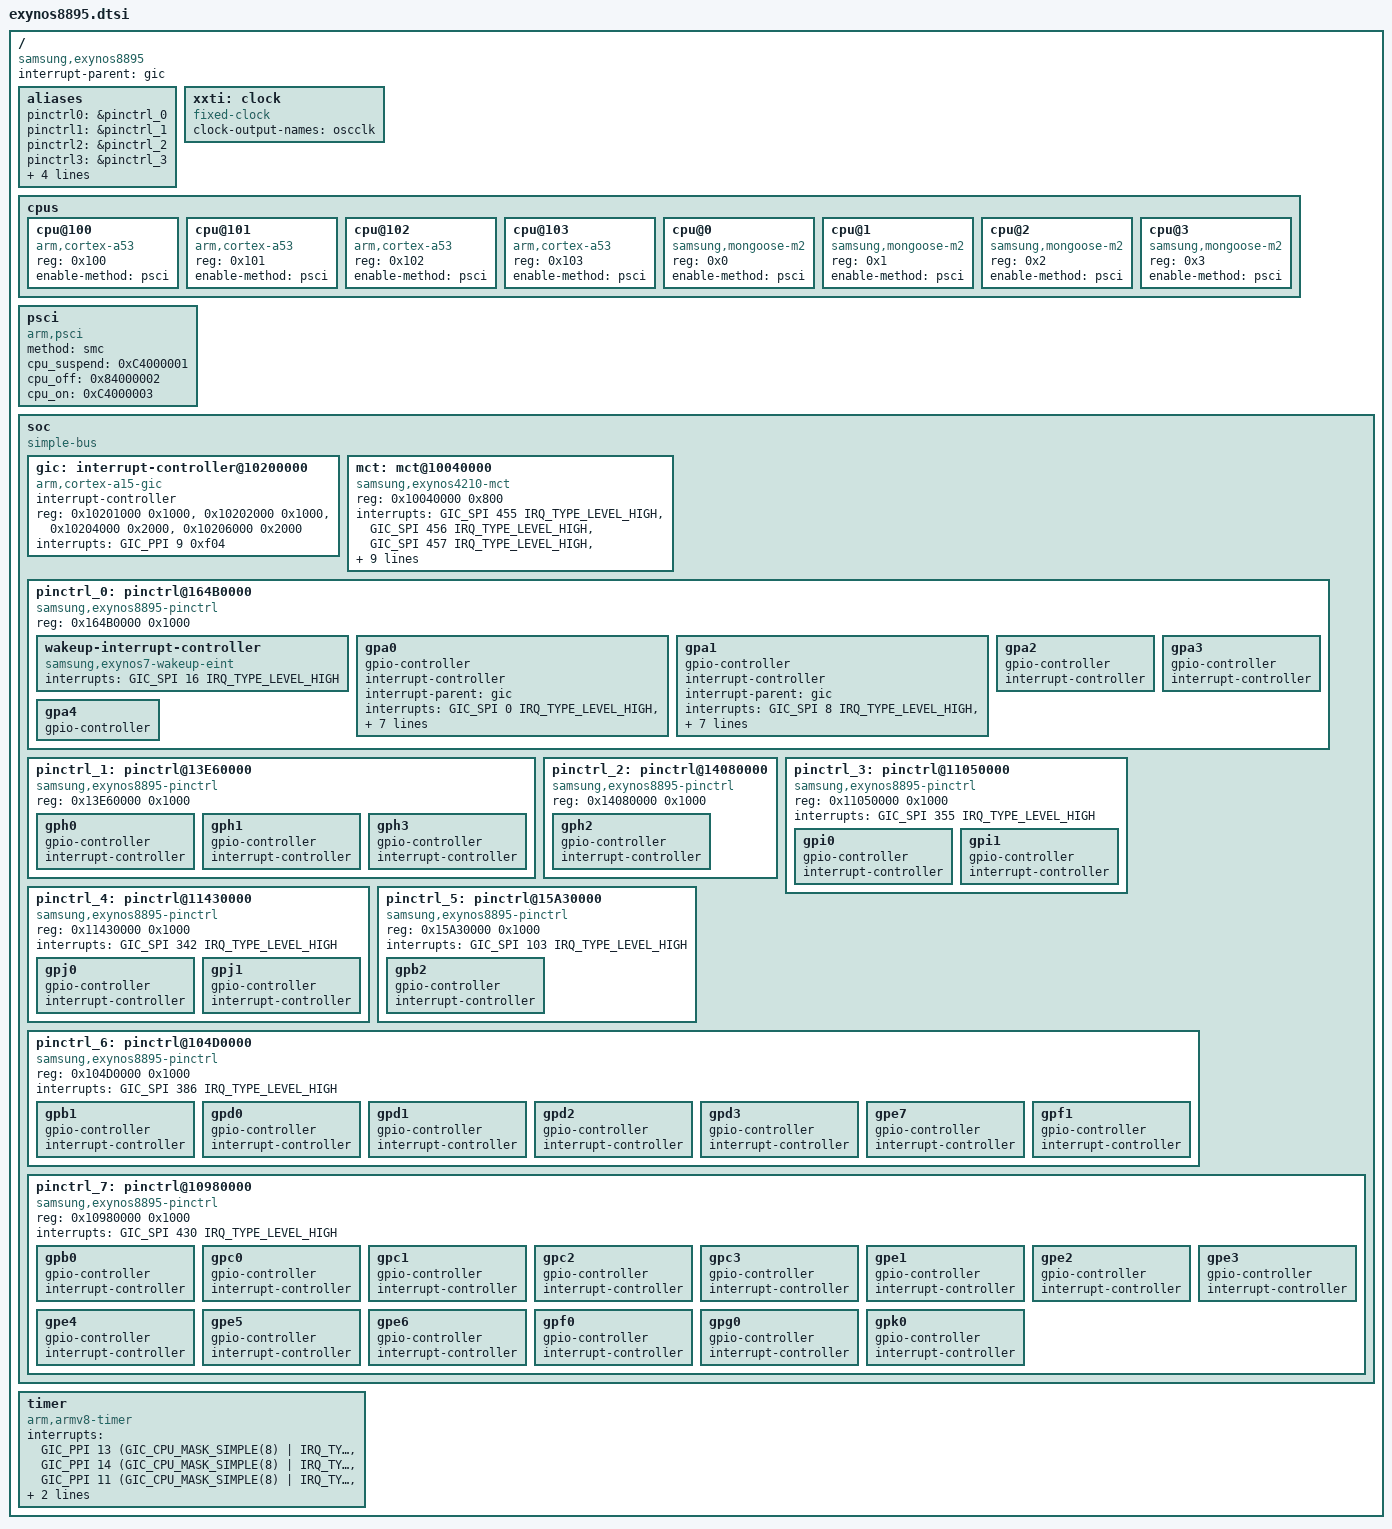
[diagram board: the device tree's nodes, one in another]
// SPDX-License-Identifier: BSD-3-Clause
/*
 * Copyright (c) 2020, Ivaylo Ivanov <ivo.ivanov@null.net>
 */

/dts-v1/;
#include <dt-bindings/interrupt-controller/arm-gic.h>

/ {
	compatible = "samsung,exynos8895";
	#address-cells = <2>;
	#size-cells = <2>;

	interrupt-parent = <&gic>;

	aliases {
		pinctrl0 = &pinctrl_0;
		pinctrl1 = &pinctrl_1;
		pinctrl2 = &pinctrl_2;
		pinctrl3 = &pinctrl_3;
		pinctrl4 = &pinctrl_4;
		pinctrl5 = &pinctrl_5;
		pinctrl6 = &pinctrl_6;
		pinctrl7 = &pinctrl_7;
	};

	xxti: clock {
		/* XXTI */
		compatible = "fixed-clock";
		clock-output-names = "oscclk";
		#clock-cells = <0>;
	};

	cpus {
		#address-cells = <1>;
		#size-cells = <0>;

		cpu@100 {
			device_type = "cpu";
			compatible = "arm,cortex-a53", "arm,armv8";
			reg = <0x100>;
			enable-method = "psci";
		};

		cpu@101 {
			device_type = "cpu";
			compatible = "arm,cortex-a53", "arm,armv8";
			reg = <0x101>;
			enable-method = "psci";
		};

		cpu@102 {
			device_type = "cpu";
			compatible = "arm,cortex-a53", "arm,armv8";
			reg = <0x102>;
			enable-method = "psci";
		};

		cpu@103 {
			device_type = "cpu";
			compatible = "arm,cortex-a53", "arm,armv8";
			reg = <0x103>;
			enable-method = "psci";
		};

		cpu@0 {
			device_type = "cpu";
			compatible = "samsung,mongoose-m2", "arm,armv8";
			reg = <0x0>;
			enable-method = "psci";
		};

		cpu@1 {
			device_type = "cpu";
			compatible = "samsung,mongoose-m2", "arm,armv8";
			reg = <0x1>;
			enable-method = "psci";
		};

		cpu@2 {
			device_type = "cpu";
			compatible = "samsung,mongoose-m2", "arm,armv8";
			reg = <0x2>;
			enable-method = "psci";
		};

		cpu@3 {
			device_type = "cpu";
			compatible = "samsung,mongoose-m2", "arm,armv8";
			reg = <0x3>;
			enable-method = "psci";
		};
	};

	psci {
		compatible = "arm,psci";
		method = "smc";
		cpu_suspend = <0xC4000001>;
		cpu_off = <0x84000002>;
		cpu_on = <0xC4000003>;
	};

	soc: soc {
		compatible = "simple-bus";
		#address-cells = <1>;
		#size-cells = <1>;
		ranges = <0 0 0 0x18000000>;

		gic: interrupt-controller@10200000 {
			compatible = "arm,cortex-a15-gic";
			#interrupt-cells = <3>;
			interrupt-controller;
			reg = <0x10201000 0x1000>,
			      <0x10202000 0x1000>,
			      <0x10204000 0x2000>,
			      <0x10206000 0x2000>;
			interrupts = <GIC_PPI 9 0xf04>;
		};

		mct: mct@10040000 {
			compatible = "samsung,exynos4210-mct";
			reg = <0x10040000 0x800>;
			interrupts = <GIC_SPI 455 IRQ_TYPE_LEVEL_HIGH>,
				<GIC_SPI 456 IRQ_TYPE_LEVEL_HIGH>,
				<GIC_SPI 457 IRQ_TYPE_LEVEL_HIGH>,
				<GIC_SPI 458 IRQ_TYPE_LEVEL_HIGH>,
				<GIC_SPI 459 IRQ_TYPE_LEVEL_HIGH>,
				<GIC_SPI 460 IRQ_TYPE_LEVEL_HIGH>,
				<GIC_SPI 461 IRQ_TYPE_LEVEL_HIGH>,
				<GIC_SPI 462 IRQ_TYPE_LEVEL_HIGH>,
				<GIC_SPI 463 IRQ_TYPE_LEVEL_HIGH>,
				<GIC_SPI 464 IRQ_TYPE_LEVEL_HIGH>,
				<GIC_SPI 465 IRQ_TYPE_LEVEL_HIGH>,
				<GIC_SPI 466 IRQ_TYPE_LEVEL_HIGH>;

			// TODO clocks
			//clocks = <&xxti>, <&cmu_peris CLK_PCLK_MCT>;
			//clock-names = "fin_pll", "mct";
		};

		pinctrl_0: pinctrl@164B0000 {
			compatible = "samsung,exynos8895-pinctrl";
			reg = <0x164B0000 0x1000>;

			wakeup-interrupt-controller {
				compatible = "samsung,exynos7-wakeup-eint";
				interrupts = <GIC_SPI 16 IRQ_TYPE_LEVEL_HIGH>;
			};

			gpa0: gpa0 {
				gpio-controller;
				#gpio-cells = <2>;

				interrupt-controller;
				interrupt-parent = <&gic>;
				#interrupt-cells = <2>;
				interrupts = <GIC_SPI 0 IRQ_TYPE_LEVEL_HIGH>,
					     <GIC_SPI 1 IRQ_TYPE_LEVEL_HIGH>,
					     <GIC_SPI 2 IRQ_TYPE_LEVEL_HIGH>,
					     <GIC_SPI 3 IRQ_TYPE_LEVEL_HIGH>,
					     <GIC_SPI 4 IRQ_TYPE_LEVEL_HIGH>,
					     <GIC_SPI 5 IRQ_TYPE_LEVEL_HIGH>,
					     <GIC_SPI 6 IRQ_TYPE_LEVEL_HIGH>,
					     <GIC_SPI 7 IRQ_TYPE_LEVEL_HIGH>;
			};

			gpa1: gpa1 {
				gpio-controller;
				#gpio-cells = <2>;

				interrupt-controller;
				interrupt-parent = <&gic>;
				#interrupt-cells = <3>;
				interrupts = <GIC_SPI 8 IRQ_TYPE_LEVEL_HIGH>,
					     <GIC_SPI 9 IRQ_TYPE_LEVEL_HIGH>,
					     <GIC_SPI 10 IRQ_TYPE_LEVEL_HIGH>,
					     <GIC_SPI 11 IRQ_TYPE_LEVEL_HIGH>,
					     <GIC_SPI 12 IRQ_TYPE_LEVEL_HIGH>,
					     <GIC_SPI 13 IRQ_TYPE_LEVEL_HIGH>,
					     <GIC_SPI 14 IRQ_TYPE_LEVEL_HIGH>,
					     <GIC_SPI 15 IRQ_TYPE_LEVEL_HIGH>;
			};

			gpa2: gpa2 {
				gpio-controller;
				#gpio-cells = <2>;

				interrupt-controller;
				#interrupt-cells = <2>;
			};

			gpa3: gpa3 {
				gpio-controller;
				#gpio-cells = <2>;

				interrupt-controller;
				#interrupt-cells = <2>;
			};

			gpa4: gpa4 {
				gpio-controller;
				#gpio-cells = <2>;
			};
		};

		pinctrl_1: pinctrl@13E60000 {
			compatible = "samsung,exynos8895-pinctrl";
			reg = <0x13E60000 0x1000>;

			gph0: gph0 {
				gpio-controller;
				#gpio-cells = <2>;

				interrupt-controller;
				#interrupt-cells = <2>;
			};

			gph1: gph1 {
				gpio-controller;
				#gpio-cells = <2>;

				interrupt-controller;
				#interrupt-cells = <2>;
			};

			gph3: gph3 {
				gpio-controller;
				#gpio-cells = <2>;

				interrupt-controller;
				#interrupt-cells = <2>;
			};
		};

		pinctrl_2: pinctrl@14080000 {
			compatible = "samsung,exynos8895-pinctrl";
			reg = <0x14080000 0x1000>;

			gph2: gph2 {
				gpio-controller;
				#gpio-cells = <2>;

				interrupt-controller;
				#interrupt-cells = <2>;
			};
		};

		pinctrl_3: pinctrl@11050000 {
			compatible = "samsung,exynos8895-pinctrl";
			reg = <0x11050000 0x1000>;
			interrupts = <GIC_SPI 355 IRQ_TYPE_LEVEL_HIGH>;

			gpi0: gpi0 {
				gpio-controller;
				#gpio-cells = <2>;

				interrupt-controller;
				#interrupt-cells = <2>;
			};

			gpi1: gpi1 {
				gpio-controller;
				#gpio-cells = <2>;

				interrupt-controller;
				#interrupt-cells = <2>;
			};
		};

		pinctrl_4: pinctrl@11430000 {
			compatible = "samsung,exynos8895-pinctrl";
			reg = <0x11430000 0x1000>;
			interrupts = <GIC_SPI 342 IRQ_TYPE_LEVEL_HIGH>;

			gpj0: gpj0 {
				gpio-controller;
				#gpio-cells = <2>;

				interrupt-controller;
				#interrupt-cells = <2>;
			};

			gpj1: gpj1 {
				gpio-controller;
				#gpio-cells = <2>;

				interrupt-controller;
				#interrupt-cells = <2>;
			};
		};

		pinctrl_5: pinctrl@15A30000 {
			compatible = "samsung,exynos8895-pinctrl";
			reg = <0x15A30000 0x1000>;
			interrupts = <GIC_SPI 103 IRQ_TYPE_LEVEL_HIGH>;

			gpb2: gpb2 {
				gpio-controller;
				#gpio-cells = <2>;

				interrupt-controller;
				#interrupt-cells = <2>;
			};
		};

		pinctrl_6: pinctrl@104D0000 {
			compatible = "samsung,exynos8895-pinctrl";
			reg = <0x104D0000 0x1000>;
			interrupts = <GIC_SPI 386 IRQ_TYPE_LEVEL_HIGH>;

			gpb1: gpb1 {
				gpio-controller;
				#gpio-cells = <2>;

				interrupt-controller;
				#interrupt-cells = <2>;
			};

			gpd0: gpd0 {
				gpio-controller;
				#gpio-cells = <2>;

				interrupt-controller;
				#interrupt-cells = <2>;
			};

			gpd1: gpd1 {
				gpio-controller;
				#gpio-cells = <2>;

				interrupt-controller;
				#interrupt-cells = <2>;
			};

			gpd2: gpd2 {
				gpio-controller;
				#gpio-cells = <2>;

				interrupt-controller;
				#interrupt-cells = <2>;
			};

			gpd3: gpd3 {
				gpio-controller;
				#gpio-cells = <2>;

				interrupt-controller;
				#interrupt-cells = <2>;
			};

			gpe7: gpe7 {
				gpio-controller;
				#gpio-cells = <2>;

				interrupt-controller;
				#interrupt-cells = <2>;
			};

			gpf1: gpf1 {
				gpio-controller;
				#gpio-cells = <2>;

				interrupt-controller;
				#interrupt-cells = <2>;
			};
		};

		pinctrl_7: pinctrl@10980000 {
			compatible = "samsung,exynos8895-pinctrl";
			reg = <0x10980000 0x1000>;
			interrupts = <GIC_SPI 430 IRQ_TYPE_LEVEL_HIGH>;

			gpb0: gpb0 {
				gpio-controller;
				#gpio-cells = <2>;

				interrupt-controller;
				#interrupt-cells = <2>;
			};

			gpc0: gpc0 {
				gpio-controller;
				#gpio-cells = <2>;

				interrupt-controller;
				#interrupt-cells = <2>;
			};

			gpc1: gpc1 {
				gpio-controller;
				#gpio-cells = <2>;

				interrupt-controller;
				#interrupt-cells = <2>;
			};

			gpc2: gpc2 {
				gpio-controller;
				#gpio-cells = <2>;

				interrupt-controller;
				#interrupt-cells = <2>;
			};

			gpc3: gpc3 {
				gpio-controller;
				#gpio-cells = <2>;

				interrupt-controller;
				#interrupt-cells = <2>;
			};

			gpe1: gpe1 {
				gpio-controller;
				#gpio-cells = <2>;

				interrupt-controller;
				#interrupt-cells = <2>;
			};

			gpe2: gpe2 {
				gpio-controller;
				#gpio-cells = <2>;

				interrupt-controller;
				#interrupt-cells = <2>;
			};

			gpe3: gpe3 {
				gpio-controller;
				#gpio-cells = <2>;

				interrupt-controller;
				#interrupt-cells = <2>;
			};

			gpe4: gpe4 {
				gpio-controller;
				#gpio-cells = <2>;

				interrupt-controller;
				#interrupt-cells = <2>;
			};

			gpe5: gpe5 {
				gpio-controller;
				#gpio-cells = <2>;

				interrupt-controller;
				#interrupt-cells = <2>;
			};

			gpe6: gpe6 {
				gpio-controller;
				#gpio-cells = <2>;

				interrupt-controller;
				#interrupt-cells = <2>;
			};

			gpf0: gpf0 {
				gpio-controller;
				#gpio-cells = <2>;

				interrupt-controller;
				#interrupt-cells = <2>;
			};

			gpg0: gpg0 {
				gpio-controller;
				#gpio-cells = <2>;

				interrupt-controller;
				#interrupt-cells = <2>;
			};

			gpk0: gpk0 {
				gpio-controller;
				#gpio-cells = <2>;

				interrupt-controller;
				#interrupt-cells = <2>;
			};
		};
	};

	timer: timer {
		compatible = "arm,armv8-timer";
		interrupts = <GIC_PPI 13
				(GIC_CPU_MASK_SIMPLE(8) | IRQ_TYPE_LEVEL_HIGH)>,
			<GIC_PPI 14
				(GIC_CPU_MASK_SIMPLE(8) | IRQ_TYPE_LEVEL_HIGH)>,
			<GIC_PPI 11
				(GIC_CPU_MASK_SIMPLE(8) | IRQ_TYPE_LEVEL_HIGH)>,
			<GIC_PPI 10
				(GIC_CPU_MASK_SIMPLE(8) | IRQ_TYPE_LEVEL_HIGH)>;
		clock-frequency = <26000000>;
	};
};
